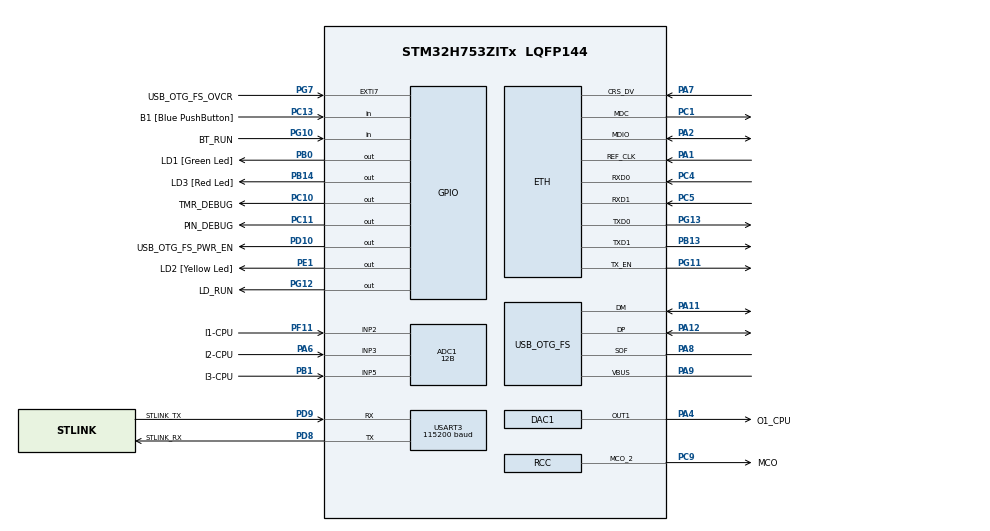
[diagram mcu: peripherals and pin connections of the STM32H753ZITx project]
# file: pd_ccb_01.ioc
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ADC1.Channel-0\#ChannelRegularConversion=ADC_CHANNEL_2
ADC1.Channel-1\#ChannelRegularConversion=ADC_CHANNEL_3
ADC1.Channel-2\#ChannelRegularConversion=ADC_CHANNEL_5
ADC1.ExternalTrigConv=ADC_EXTERNALTRIG_T1_TRGO2
ADC1.NbrOfConversion=3
ADC1.NbrOfConversionFlag=1
ADC1.OffsetNumber-0\#ChannelRegularConversion=ADC_OFFSET_NONE
ADC1.OffsetNumber-1\#ChannelRegularConversion=ADC_OFFSET_NONE
ADC1.OffsetNumber-2\#ChannelRegularConversion=ADC_OFFSET_NONE
ADC1.OffsetSignedSaturation-0\#ChannelRegularConversion=DISABLE
ADC1.OversamplingMode=ENABLE
ADC1.Rank-0\#ChannelRegularConversion=1
ADC1.Rank-1\#ChannelRegularConversion=2
ADC1.Rank-2\#ChannelRegularConversion=3
ADC1.Ratio=8
ADC1.Resolution=ADC_RESOLUTION_12B
ADC1.RightBitShift=ADC_RIGHTBITSHIFT_3
ADC1.SamplingTime-0\#ChannelRegularConversion=ADC_SAMPLETIME_2CYCLES_5
ADC1.SamplingTime-1\#ChannelRegularConversion=ADC_SAMPLETIME_2CYCLES_5
ADC1.SamplingTime-2\#ChannelRegularConversion=ADC_SAMPLETIME_2CYCLES_5
ADC1.master=1
CORTEX_M7.CPU_DCache=Disabled
CORTEX_M7.CPU_ICache=Disabled
CORTEX_M7.MPU_Control=__NULL
DAC1.DAC1_OutputBuffer-DAC_OUT1=DAC_OUTPUTBUFFER_DISABLE
DAC1.DAC_Channel-DAC_OUT1=DAC_CHANNEL_1
ETH.ETH_RX_DESC_CNT=4
ETH.ETH_TX_DESC_CNT=4
ETH.MACAddr=00\:80\:E1\:00\:00\:00
ETH.MediaInterface=HAL_ETH_RMII_MODE
ETH.RxBuffAddress=0x30040200
ETH.RxBuffLen=1524
ETH.RxDescAddress=0x30040000
ETH.TxDescAddress=0x30040060
Mcu.Family=STM32H7
Mcu.Name=STM32H753ZITx
Mcu.Package=LQFP144
NVIC.ADC_IRQn=true\:0\:0\:false\:false\:true\:true\:true\:true
NVIC.PriorityGroup=NVIC_PRIORITYGROUP_4
NVIC.TIM1_UP_IRQn=true\:1\:0\:true\:false\:true\:true\:true\:true
NVIC.USART3_IRQn=true\:0\:0\:false\:false\:true\:true\:true\:true
PA1.Mode=RMII
PA1.Signal=ETH_REF_CLK
PA11.Mode=Device_Only
PA11.Signal=USB_OTG_FS_DM
PA12.Mode=Device_Only
PA12.Signal=USB_OTG_FS_DP
PA2.Mode=RMII
PA2.Signal=ETH_MDIO
PA4.GPIO_Label=O1_CPU
PA4.Signal=COMP_DAC11_group
PA6.GPIO_Label=I2-CPU
PA6.Signal=ADCx_INP3
PA7.Mode=RMII
PA7.Signal=ETH_CRS_DV
PA8.Mode=Activate_SOF_FS
PA8.Signal=USB_OTG_FS_SOF
PA9.Mode=Activate_VBUS
PA9.Signal=USB_OTG_FS_VBUS
PB0.GPIO_Label=LD1 [Green Led]
PB0.Signal=GPIO_Output
PB1.GPIO_Label=I3-CPU
PB1.Signal=ADCx_INP5
PB13.Mode=RMII
PB13.Signal=ETH_TXD1
PB14.GPIO_Label=LD3 [Red Led]
PB14.Signal=GPIO_Output
PC1.Mode=RMII
PC1.Signal=ETH_MDC
PC10.GPIO_Label=TMR_DEBUG
PC10.Signal=GPIO_Output
PC11.GPIO_Label=PIN_DEBUG
PC11.Signal=GPIO_Output
PC13.GPIO_Label=B1 [Blue PushButton]
PC13.Signal=GPIO_Input
PC14-OSC32_IN\ (OSC32_IN).Mode=LSE-External-Oscillator
PC14-OSC32_IN\ (OSC32_IN).Signal=RCC_OSC32_IN
PC15-OSC32_OUT\ (OSC32_OUT).Mode=LSE-External-Oscillator
PC15-OSC32_OUT\ (OSC32_OUT).Signal=RCC_OSC32_OUT
PC4.Mode=RMII
PC4.Signal=ETH_RXD0
PC5.Mode=RMII
PC5.Signal=ETH_RXD1
PC9.GPIO_Label=MCO
PC9.GPIO_Speed=GPIO_SPEED_FREQ_VERY_HIGH
PC9.Mode=Clock-out-2
PC9.Signal=RCC_MCO_2
PD10.GPIO_Label=USB_OTG_FS_PWR_EN
PD10.Signal=GPIO_Output
PD8.GPIO_Label=STLINK_RX
PD8.Mode=Asynchronous
PD8.Signal=USART3_TX
PD9.GPIO_Label=STLINK_TX
PD9.Mode=Asynchronous
PD9.Signal=USART3_RX
PE1.GPIO_Label=LD2 [Yellow Led]
PE1.Signal=GPIO_Output
PF11.GPIO_Label=I1-CPU
PF11.Mode=IN2-Single-Ended
PF11.Signal=ADC1_INP2
PG10.GPIO_Label=BT_RUN
PG10.GPIO_PuPd=GPIO_PULLUP
PG10.Signal=GPIO_Input
PG11.Mode=RMII
PG11.Signal=ETH_TX_EN
PG12.GPIO_Label=LD_RUN
PG12.Signal=GPIO_Output
PG13.Mode=RMII
PG13.Signal=ETH_TXD0
PG7.GPIO_Label=USB_OTG_FS_OVCR
PG7.Signal=GPXTI7
PH0-OSC_IN\ (PH0).Mode=HSE-External-Clock-Source
PH0-OSC_IN\ (PH0).Signal=RCC_OSC_IN
PH1-OSC_OUT\ (PH1).Signal=RCC_OSC_OUT
ProjectManager.HeapSize=0x200
ProjectManager.StackSize=0x400
ProjectManager.TargetToolchain=STM32CubeIDE
RCC.ADCFreq_Value=80000000
RCC.APB1Freq_Value=120000000
RCC.APB2Freq_Value=120000000
RCC.APB3Freq_Value=120000000
RCC.APB4Freq_Value=120000000
RCC.CortexFreq_Value=480000000
RCC.D1PPRE=RCC_APB3_DIV2
RCC.D2PPRE1=RCC_APB1_DIV2
RCC.D2PPRE2=RCC_APB2_DIV2
RCC.D3PPRE=RCC_APB4_DIV2
RCC.DIVM1=4
RCC.DIVM2=4
RCC.DIVM3=4
RCC.DIVN1=480
RCC.DIVN2=80
RCC.DIVN3=120
RCC.DIVQ1=8
RCC.HCLKFreq_Value=240000000
RCC.HPRE=RCC_HCLK_DIV2
RCC.HSE_VALUE=8000000
RCC.PLL2FRACN=0
RCC.PLL2_VCI_Range-AdvancedSettings=RCC_PLL2VCIRANGE_3
RCC.PLL3FRACN=0
RCC.PLLFRACN=0
RCC.PLLSourceVirtual=RCC_PLLSOURCE_HSE
RCC.PWR_Regulator_Voltage_Scale=PWR_REGULATOR_VOLTAGE_SCALE0
RCC.RCC_MCO2Source=RCC_MCO2SOURCE_HSE
RCC.RCC_TIM_PRescaler_Selection=RCC_TIMPRES_ACTIVATED
RCC.SYSCLKFreq_VALUE=480000000
RCC.SYSCLKSource=RCC_SYSCLKSOURCE_PLLCLK
RCC.USBCLockSelection=RCC_USBCLKSOURCE_HSI48
RCC.USBFreq_Value=48000000
SH.ADCx_INP3.0=ADC1_INP3,IN3-Single-Ended
SH.ADCx_INP5.0=ADC1_INP5,IN5-Single-Ended
SH.COMP_DAC11_group.0=DAC1_OUT1,DAC_OUT1
TIM1.Period=1008
TIM1.Prescaler=240
TIM1.TIM_MasterOutputTrigger2=TIM_TRGO2_UPDATE
USART3.AutoBaudRateEnableParam=UART_ADVFEATURE_AUTOBAUDRATE_DISABLE
USART3.BaudRate=115200
USART3.ClockPrescaler=PRESCALER_DIV1
USART3.DMADisableonRxErrorParam=ADVFEATURE_DMA_ENABLEONRXERROR
USART3.DataInvertParam=ADVFEATURE_DATAINV_DISABLE
USART3.FIFOMode=FIFOMODE_DISABLE
USART3.MSBFirstParam=ADVFEATURE_MSBFIRST_DISABLE
USART3.Mode=MODE_TX_RX
USART3.OneBitSampling=UART_ONE_BIT_SAMPLE_DISABLE
USART3.OverSampling=UART_OVERSAMPLING_16
USART3.OverrunDisableParam=ADVFEATURE_OVERRUN_ENABLE
USART3.Parity=PARITY_NONE
USART3.RXFIFOThreshold=RXFIFO_THRESHOLD_1EIGHTHFULL
USART3.RxPinLevelInvertParam=ADVFEATURE_RXINV_DISABLE
USART3.StopBits=STOPBITS_1
USART3.SwapParam=ADVFEATURE_SWAP_DISABLE
USART3.TXFIFOThreshold=TXFIFO_THRESHOLD_1EIGHTHFULL
USART3.TxPinLevelInvertParam=ADVFEATURE_TXINV_DISABLE
USART3.VirtualMode-Asynchronous=VM_ASYNC
USART3.WordLength=WORDLENGTH_8B
USB_OTG_FS.Sof_enable=ENABLE
USB_OTG_FS.VirtualMode=Device_Only
USB_OTG_FS.battery_charging_enable=ENABLE
USB_OTG_FS.low_power_enable=DISABLE
USB_OTG_FS.lpm_enable=DISABLE
USB_OTG_FS.use_dedicated_ep1=DISABLE
USB_OTG_FS.vbus_sensing_enable=ENABLE
VP_TIM1_VS_ClockSourceINT.Mode=Internal
VREF+.Mode=InternalMode
VREF+.Signal=VREFBUF_OUT
board=NUCLEO-H753ZI

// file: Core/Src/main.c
/* USER CODE BEGIN Header */
/**
  ******************************************************************************
  * @file           : main.c
  * @brief          : Main program body
  ******************************************************************************
  * @attention
  *
  * Copyright (c) 2022 STMicroelectronics.
  * All rights reserved.
  *
  * This software is licensed under terms that can be found in the LICENSE file
  * in the root directory of this software component.
  * If no LICENSE file comes with this software, it is provided AS-IS.
  *
  ******************************************************************************
  */
/* USER CODE END Header */
#include "main.h"
#include "string.h"

/* USER CODE BEGIN Includes */
#include "app.h"
/* USER CODE END Includes */

#if defined ( __ICCARM__ ) /*!< IAR Compiler */
#pragma location=0x30040000
ETH_DMADescTypeDef  DMARxDscrTab[ETH_RX_DESC_CNT]; /* Ethernet Rx DMA Descriptors */
#pragma location=0x30040060
ETH_DMADescTypeDef  DMATxDscrTab[ETH_TX_DESC_CNT]; /* Ethernet Tx DMA Descriptors */

#elif defined ( __CC_ARM )  /* MDK ARM Compiler */

__attribute__((at(0x30040000))) ETH_DMADescTypeDef  DMARxDscrTab[ETH_RX_DESC_CNT]; /* Ethernet Rx DMA Descriptors */
__attribute__((at(0x30040060))) ETH_DMADescTypeDef  DMATxDscrTab[ETH_TX_DESC_CNT]; /* Ethernet Tx DMA Descriptors */

#elif defined ( __GNUC__ ) /* GNU Compiler */
ETH_DMADescTypeDef DMARxDscrTab[ETH_RX_DESC_CNT] __attribute__((section(".RxDecripSection"))); /* Ethernet Rx DMA Descriptors */
ETH_DMADescTypeDef DMATxDscrTab[ETH_TX_DESC_CNT] __attribute__((section(".TxDecripSection")));   /* Ethernet Tx DMA Descriptors */

#endif

ETH_TxPacketConfig TxConfig;

ADC_HandleTypeDef hadc1;

DAC_HandleTypeDef hdac1;

ETH_HandleTypeDef heth;

TIM_HandleTypeDef htim1;

UART_HandleTypeDef huart3;

PCD_HandleTypeDef hpcd_USB_OTG_FS;

void SystemClock_Config(void);
void PeriphCommonClock_Config(void);
static void MX_GPIO_Init(void);
static void MX_ETH_Init(void);
static void MX_USART3_UART_Init(void);
static void MX_USB_OTG_FS_PCD_Init(void);
static void MX_ADC1_Init(void);
static void MX_DAC1_Init(void);
static void MX_TIM1_Init(void);

int main(void)
{

  /* MCU Configuration--------------------------------------------------------*/

  /* Reset of all peripherals, Initializes the Flash interface and the Systick. */
  HAL_Init();

  /* Configure the system clock */
  SystemClock_Config();

/* Configure the peripherals common clocks */
  PeriphCommonClock_Config();

  /* Initialize all configured peripherals */
  MX_GPIO_Init();
  MX_ETH_Init();
  MX_USART3_UART_Init();
  MX_USB_OTG_FS_PCD_Init();
  MX_ADC1_Init();
  MX_DAC1_Init();
  MX_TIM1_Init();
  /* USER CODE BEGIN 2 */

  // App setup
  app_setup();

  /* USER CODE END 2 */

  /* Infinite loop */
  while (1)
  {

    /* USER CODE BEGIN 3 */
	  // App loop
	  app_loop();
  }
  /* USER CODE END 3 */
}

void SystemClock_Config(void)
{
  RCC_OscInitTypeDef RCC_OscInitStruct = {0};
  RCC_ClkInitTypeDef RCC_ClkInitStruct = {0};

  /** Supply configuration update enable
  */
  HAL_PWREx_ConfigSupply(PWR_LDO_SUPPLY);

  /** Configure the main internal regulator output voltage
  */

  while(!__HAL_PWR_GET_FLAG(PWR_FLAG_VOSRDY)) {}

  /** Initializes the RCC Oscillators according to the specified parameters
  * in the RCC_OscInitTypeDef structure.
  */
  RCC_OscInitStruct.OscillatorType = RCC_OSCILLATORTYPE_HSI48|RCC_OSCILLATORTYPE_HSE;
  RCC_OscInitStruct.HSEState = RCC_HSE_BYPASS;
  RCC_OscInitStruct.HSI48State = RCC_HSI48_ON;
  RCC_OscInitStruct.PLL.PLLState = RCC_PLL_ON;
  RCC_OscInitStruct.PLL.PLLSource = RCC_PLLSOURCE_HSE;
  RCC_OscInitStruct.PLL.PLLM = 4;
  RCC_OscInitStruct.PLL.PLLN = 480;
  RCC_OscInitStruct.PLL.PLLP = 2;
  RCC_OscInitStruct.PLL.PLLQ = 8;
  RCC_OscInitStruct.PLL.PLLR = 2;
  RCC_OscInitStruct.PLL.PLLRGE = RCC_PLL1VCIRANGE_1;
  RCC_OscInitStruct.PLL.PLLVCOSEL = RCC_PLL1VCOWIDE;
  RCC_OscInitStruct.PLL.PLLFRACN = 0;
  if (HAL_RCC_OscConfig(&RCC_OscInitStruct) != HAL_OK)
  {
    Error_Handler();
  }

  /** Initializes the CPU, AHB and APB buses clocks
  */
  RCC_ClkInitStruct.ClockType = RCC_CLOCKTYPE_HCLK|RCC_CLOCKTYPE_SYSCLK
                              |RCC_CLOCKTYPE_PCLK1|RCC_CLOCKTYPE_PCLK2
                              |RCC_CLOCKTYPE_D3PCLK1|RCC_CLOCKTYPE_D1PCLK1;
  RCC_ClkInitStruct.SYSCLKSource = RCC_SYSCLKSOURCE_PLLCLK;
  RCC_ClkInitStruct.SYSCLKDivider = RCC_SYSCLK_DIV1;
  RCC_ClkInitStruct.AHBCLKDivider = RCC_HCLK_DIV2;
  RCC_ClkInitStruct.APB3CLKDivider = RCC_APB3_DIV2;
  RCC_ClkInitStruct.APB1CLKDivider = RCC_APB1_DIV2;
  RCC_ClkInitStruct.APB2CLKDivider = RCC_APB2_DIV2;
  RCC_ClkInitStruct.APB4CLKDivider = RCC_APB4_DIV2;

  if (HAL_RCC_ClockConfig(&RCC_ClkInitStruct, FLASH_LATENCY_0) != HAL_OK)
  {
    Error_Handler();
  }
  HAL_RCC_MCOConfig(RCC_MCO2, RCC_MCO2SOURCE_HSE, RCC_MCODIV_1);
}

void PeriphCommonClock_Config(void)
{
  RCC_PeriphCLKInitTypeDef PeriphClkInitStruct = {0};

  /** Initializes the peripherals clock
  */
  PeriphClkInitStruct.PeriphClockSelection = RCC_PERIPHCLK_TIM;
  PeriphClkInitStruct.TIMPresSelection = RCC_TIMPRES_ACTIVATED;

  if (HAL_RCCEx_PeriphCLKConfig(&PeriphClkInitStruct) != HAL_OK)
  {
    Error_Handler();
  }
}

static void MX_ADC1_Init(void)
{

  ADC_MultiModeTypeDef multimode = {0};
  ADC_ChannelConfTypeDef sConfig = {0};

  /* USER CODE BEGIN ADC1_Init 1 */
  // Asynchronous clock mode, input ADC clock divided by 128
  hadc1.Init.ClockPrescaler = ADC_CLOCK_ASYNC_DIV128;
  /* USER CODE END ADC1_Init 1 */

  /** Common config
  */
  hadc1.Instance = ADC1;
  hadc1.Init.ClockPrescaler = ADC_CLOCK_ASYNC_DIV1;
  hadc1.Init.Resolution = ADC_RESOLUTION_12B;
  hadc1.Init.ScanConvMode = ADC_SCAN_ENABLE;
  hadc1.Init.EOCSelection = ADC_EOC_SINGLE_CONV;
  hadc1.Init.LowPowerAutoWait = DISABLE;
  hadc1.Init.ContinuousConvMode = DISABLE;
  hadc1.Init.NbrOfConversion = 3;
  hadc1.Init.DiscontinuousConvMode = DISABLE;
  hadc1.Init.ExternalTrigConv = ADC_EXTERNALTRIG_T1_TRGO2;
  hadc1.Init.ExternalTrigConvEdge = ADC_EXTERNALTRIGCONVEDGE_RISING;
  hadc1.Init.ConversionDataManagement = ADC_CONVERSIONDATA_DR;
  hadc1.Init.Overrun = ADC_OVR_DATA_PRESERVED;
  hadc1.Init.LeftBitShift = ADC_LEFTBITSHIFT_NONE;
  hadc1.Init.OversamplingMode = ENABLE;
  hadc1.Init.Oversampling.Ratio = 8;
  hadc1.Init.Oversampling.RightBitShift = ADC_RIGHTBITSHIFT_3;
  hadc1.Init.Oversampling.TriggeredMode = ADC_TRIGGEREDMODE_SINGLE_TRIGGER;
  hadc1.Init.Oversampling.OversamplingStopReset = ADC_REGOVERSAMPLING_CONTINUED_MODE;
  if (HAL_ADC_Init(&hadc1) != HAL_OK)
  {
    Error_Handler();
  }

  /** Configure the ADC multi-mode
  */
  multimode.Mode = ADC_MODE_INDEPENDENT;
  if (HAL_ADCEx_MultiModeConfigChannel(&hadc1, &multimode) != HAL_OK)
  {
    Error_Handler();
  }

  /** Configure Regular Channel
  */
  sConfig.Channel = ADC_CHANNEL_2;
  sConfig.Rank = ADC_REGULAR_RANK_1;
  sConfig.SamplingTime = ADC_SAMPLETIME_2CYCLES_5;
  sConfig.SingleDiff = ADC_SINGLE_ENDED;
  sConfig.OffsetNumber = ADC_OFFSET_NONE;
  sConfig.Offset = 0;
  sConfig.OffsetSignedSaturation = DISABLE;
  if (HAL_ADC_ConfigChannel(&hadc1, &sConfig) != HAL_OK)
  {
    Error_Handler();
  }

  /** Configure Regular Channel
  */
  sConfig.Channel = ADC_CHANNEL_3;
  sConfig.Rank = ADC_REGULAR_RANK_2;
  if (HAL_ADC_ConfigChannel(&hadc1, &sConfig) != HAL_OK)
  {
    Error_Handler();
  }

  /** Configure Regular Channel
  */
  sConfig.Channel = ADC_CHANNEL_5;
  sConfig.Rank = ADC_REGULAR_RANK_3;
  if (HAL_ADC_ConfigChannel(&hadc1, &sConfig) != HAL_OK)
  {
    Error_Handler();
  }

}

static void MX_DAC1_Init(void)
{

  DAC_ChannelConfTypeDef sConfig = {0};

  /** DAC Initialization
  */
  hdac1.Instance = DAC1;
  if (HAL_DAC_Init(&hdac1) != HAL_OK)
  {
    Error_Handler();
  }

  /** DAC channel OUT1 config
  */
  sConfig.DAC_SampleAndHold = DAC_SAMPLEANDHOLD_DISABLE;
  sConfig.DAC_Trigger = DAC_TRIGGER_NONE;
  sConfig.DAC_OutputBuffer = DAC_OUTPUTBUFFER_DISABLE;
  sConfig.DAC_ConnectOnChipPeripheral = DAC_CHIPCONNECT_DISABLE;
  sConfig.DAC_UserTrimming = DAC_TRIMMING_FACTORY;
  if (HAL_DAC_ConfigChannel(&hdac1, &sConfig, DAC_CHANNEL_1) != HAL_OK)
  {
    Error_Handler();
  }

}

static void MX_ETH_Init(void)
{

   static uint8_t MACAddr[6];

  heth.Instance = ETH;
  MACAddr[0] = 0x00;
  MACAddr[1] = 0x80;
  MACAddr[2] = 0xE1;
  MACAddr[3] = 0x00;
  MACAddr[4] = 0x00;
  MACAddr[5] = 0x00;
  heth.Init.MACAddr = &MACAddr[0];
  heth.Init.MediaInterface = HAL_ETH_RMII_MODE;
  heth.Init.TxDesc = DMATxDscrTab;
  heth.Init.RxDesc = DMARxDscrTab;
  heth.Init.RxBuffLen = 1524;

  if (HAL_ETH_Init(&heth) != HAL_OK)
  {
    Error_Handler();
  }

  memset(&TxConfig, 0 , sizeof(ETH_TxPacketConfig));
  TxConfig.Attributes = ETH_TX_PACKETS_FEATURES_CSUM | ETH_TX_PACKETS_FEATURES_CRCPAD;
  TxConfig.ChecksumCtrl = ETH_CHECKSUM_IPHDR_PAYLOAD_INSERT_PHDR_CALC;
  TxConfig.CRCPadCtrl = ETH_CRC_PAD_INSERT;

}

static void MX_TIM1_Init(void)
{

  TIM_ClockConfigTypeDef sClockSourceConfig = {0};
  TIM_MasterConfigTypeDef sMasterConfig = {0};

  htim1.Instance = TIM1;
  htim1.Init.Prescaler = 240;
  htim1.Init.CounterMode = TIM_COUNTERMODE_UP;
  htim1.Init.Period = 1008;
  htim1.Init.ClockDivision = TIM_CLOCKDIVISION_DIV1;
  htim1.Init.RepetitionCounter = 0;
  htim1.Init.AutoReloadPreload = TIM_AUTORELOAD_PRELOAD_DISABLE;
  if (HAL_TIM_Base_Init(&htim1) != HAL_OK)
  {
    Error_Handler();
  }
  sClockSourceConfig.ClockSource = TIM_CLOCKSOURCE_INTERNAL;
  if (HAL_TIM_ConfigClockSource(&htim1, &sClockSourceConfig) != HAL_OK)
  {
    Error_Handler();
  }
  sMasterConfig.MasterOutputTrigger = TIM_TRGO_RESET;
  sMasterConfig.MasterOutputTrigger2 = TIM_TRGO2_UPDATE;
  sMasterConfig.MasterSlaveMode = TIM_MASTERSLAVEMODE_DISABLE;
  if (HAL_TIMEx_MasterConfigSynchronization(&htim1, &sMasterConfig) != HAL_OK)
  {
    Error_Handler();
  }
  /* USER CODE BEGIN TIM1_Init 2 */
  if (HAL_TIM_Base_Start_IT(&htim1) != HAL_OK)
  {
    /* Starting Error */
    Error_Handler();
  }
  /* USER CODE END TIM1_Init 2 */

}

static void MX_USART3_UART_Init(void)
{

  huart3.Instance = USART3;
  huart3.Init.BaudRate = 115200;
  huart3.Init.WordLength = UART_WORDLENGTH_8B;
  huart3.Init.StopBits = UART_STOPBITS_1;
  huart3.Init.Parity = UART_PARITY_NONE;
  huart3.Init.Mode = UART_MODE_TX_RX;
  huart3.Init.HwFlowCtl = UART_HWCONTROL_NONE;
  huart3.Init.OverSampling = UART_OVERSAMPLING_16;
  huart3.Init.OneBitSampling = UART_ONE_BIT_SAMPLE_DISABLE;
  huart3.Init.ClockPrescaler = UART_PRESCALER_DIV1;
  huart3.AdvancedInit.AdvFeatureInit = UART_ADVFEATURE_NO_INIT;
  if (HAL_UART_Init(&huart3) != HAL_OK)
  {
    Error_Handler();
  }
  if (HAL_UARTEx_SetTxFifoThreshold(&huart3, UART_TXFIFO_THRESHOLD_1_8) != HAL_OK)
  {
    Error_Handler();
  }
  if (HAL_UARTEx_SetRxFifoThreshold(&huart3, UART_RXFIFO_THRESHOLD_1_8) != HAL_OK)
  {
    Error_Handler();
  }
  if (HAL_UARTEx_DisableFifoMode(&huart3) != HAL_OK)
  {
    Error_Handler();
  }

}

static void MX_USB_OTG_FS_PCD_Init(void)
{

  hpcd_USB_OTG_FS.Instance = USB_OTG_FS;
  hpcd_USB_OTG_FS.Init.dev_endpoints = 9;
  hpcd_USB_OTG_FS.Init.speed = PCD_SPEED_FULL;
  hpcd_USB_OTG_FS.Init.dma_enable = DISABLE;
  hpcd_USB_OTG_FS.Init.phy_itface = PCD_PHY_EMBEDDED;
  hpcd_USB_OTG_FS.Init.Sof_enable = ENABLE;
  hpcd_USB_OTG_FS.Init.low_power_enable = DISABLE;
  hpcd_USB_OTG_FS.Init.lpm_enable = DISABLE;
  hpcd_USB_OTG_FS.Init.battery_charging_enable = ENABLE;
  hpcd_USB_OTG_FS.Init.vbus_sensing_enable = ENABLE;
  hpcd_USB_OTG_FS.Init.use_dedicated_ep1 = DISABLE;
  if (HAL_PCD_Init(&hpcd_USB_OTG_FS) != HAL_OK)
  {
    Error_Handler();
  }

}

static void MX_GPIO_Init(void)
{
  GPIO_InitTypeDef GPIO_InitStruct = {0};

  /* GPIO Ports Clock Enable */
  __HAL_RCC_GPIOC_CLK_ENABLE();
  __HAL_RCC_GPIOH_CLK_ENABLE();
  __HAL_RCC_GPIOA_CLK_ENABLE();
  __HAL_RCC_GPIOB_CLK_ENABLE();
  __HAL_RCC_GPIOF_CLK_ENABLE();
  __HAL_RCC_GPIOD_CLK_ENABLE();
  __HAL_RCC_GPIOG_CLK_ENABLE();
  __HAL_RCC_GPIOE_CLK_ENABLE();

  /*Configure GPIO pin Output Level */
  HAL_GPIO_WritePin(GPIOB, LD1_Pin|LD3_Pin, GPIO_PIN_RESET);

  /*Configure GPIO pin Output Level */
  HAL_GPIO_WritePin(USB_OTG_FS_PWR_EN_GPIO_Port, USB_OTG_FS_PWR_EN_Pin, GPIO_PIN_RESET);

  /*Configure GPIO pin Output Level */
  HAL_GPIO_WritePin(GPIOC, TMR_DEBUG_Pin|PIN_DEBUG_Pin, GPIO_PIN_RESET);

  /*Configure GPIO pin Output Level */
  HAL_GPIO_WritePin(LD_RUN_GPIO_Port, LD_RUN_Pin, GPIO_PIN_RESET);

  /*Configure GPIO pin Output Level */
  HAL_GPIO_WritePin(LD2_GPIO_Port, LD2_Pin, GPIO_PIN_RESET);

  /*Configure GPIO pin : B1_Pin */
  GPIO_InitStruct.Pin = B1_Pin;
  GPIO_InitStruct.Mode = GPIO_MODE_INPUT;
  GPIO_InitStruct.Pull = GPIO_NOPULL;
  HAL_GPIO_Init(B1_GPIO_Port, &GPIO_InitStruct);

  /*Configure GPIO pins : LD1_Pin LD3_Pin */
  GPIO_InitStruct.Pin = LD1_Pin|LD3_Pin;
  GPIO_InitStruct.Mode = GPIO_MODE_OUTPUT_PP;
  GPIO_InitStruct.Pull = GPIO_NOPULL;
  GPIO_InitStruct.Speed = GPIO_SPEED_FREQ_LOW;
  HAL_GPIO_Init(GPIOB, &GPIO_InitStruct);

  /*Configure GPIO pin : USB_OTG_FS_PWR_EN_Pin */
  GPIO_InitStruct.Pin = USB_OTG_FS_PWR_EN_Pin;
  GPIO_InitStruct.Mode = GPIO_MODE_OUTPUT_PP;
  GPIO_InitStruct.Pull = GPIO_NOPULL;
  GPIO_InitStruct.Speed = GPIO_SPEED_FREQ_LOW;
  HAL_GPIO_Init(USB_OTG_FS_PWR_EN_GPIO_Port, &GPIO_InitStruct);

  /*Configure GPIO pin : USB_OTG_FS_OVCR_Pin */
  GPIO_InitStruct.Pin = USB_OTG_FS_OVCR_Pin;
  GPIO_InitStruct.Mode = GPIO_MODE_IT_RISING;
  GPIO_InitStruct.Pull = GPIO_NOPULL;
  HAL_GPIO_Init(USB_OTG_FS_OVCR_GPIO_Port, &GPIO_InitStruct);

  /*Configure GPIO pin : MCO_Pin */
  GPIO_InitStruct.Pin = MCO_Pin;
  GPIO_InitStruct.Mode = GPIO_MODE_AF_PP;
  GPIO_InitStruct.Pull = GPIO_NOPULL;
  GPIO_InitStruct.Speed = GPIO_SPEED_FREQ_VERY_HIGH;
  GPIO_InitStruct.Alternate = GPIO_AF0_MCO;
  HAL_GPIO_Init(MCO_GPIO_Port, &GPIO_InitStruct);

  /*Configure GPIO pins : TMR_DEBUG_Pin PIN_DEBUG_Pin */
  GPIO_InitStruct.Pin = TMR_DEBUG_Pin|PIN_DEBUG_Pin;
  GPIO_InitStruct.Mode = GPIO_MODE_OUTPUT_PP;
  GPIO_InitStruct.Pull = GPIO_NOPULL;
  GPIO_InitStruct.Speed = GPIO_SPEED_FREQ_LOW;
  HAL_GPIO_Init(GPIOC, &GPIO_InitStruct);

  /*Configure GPIO pin : BT_RUN_Pin */
  GPIO_InitStruct.Pin = BT_RUN_Pin;
  GPIO_InitStruct.Mode = GPIO_MODE_INPUT;
  GPIO_InitStruct.Pull = GPIO_PULLUP;
  HAL_GPIO_Init(BT_RUN_GPIO_Port, &GPIO_InitStruct);

  /*Configure GPIO pin : LD_RUN_Pin */
  GPIO_InitStruct.Pin = LD_RUN_Pin;
  GPIO_InitStruct.Mode = GPIO_MODE_OUTPUT_PP;
  GPIO_InitStruct.Pull = GPIO_NOPULL;
  GPIO_InitStruct.Speed = GPIO_SPEED_FREQ_LOW;
  HAL_GPIO_Init(LD_RUN_GPIO_Port, &GPIO_InitStruct);

  /*Configure GPIO pin : LD2_Pin */
  GPIO_InitStruct.Pin = LD2_Pin;
  GPIO_InitStruct.Mode = GPIO_MODE_OUTPUT_PP;
  GPIO_InitStruct.Pull = GPIO_NOPULL;
  GPIO_InitStruct.Speed = GPIO_SPEED_FREQ_LOW;
  HAL_GPIO_Init(LD2_GPIO_Port, &GPIO_InitStruct);

}

void Error_Handler(void)
{
  __disable_irq();
  while (1)
  {
  }
}
